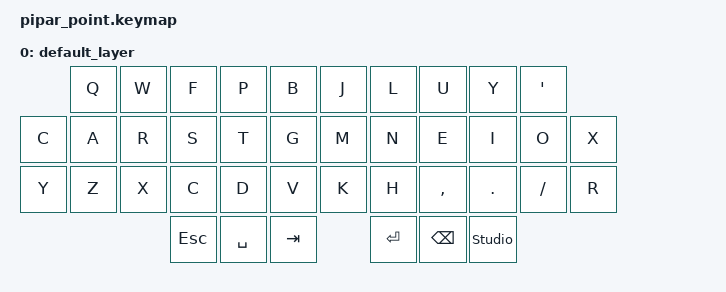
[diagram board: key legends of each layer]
#include <dt-bindings/zmk/keys.h>
#include <behaviors.dtsi>
/ {
    keymap {
        compatible = "zmk,keymap";
        default_layer {
            bindings = <
            &kp Q   &kp W   &kp F   &kp P   &kp B       &kp J   &kp L   &kp U       &kp Y       &kp SQT
    &kp C   &kp A   &kp R   &kp S   &kp T   &kp G       &kp M   &kp N   &kp E       &kp I       &kp O       &kp X
    &kp Y   &kp Z   &kp X   &kp C   &kp D   &kp V       &kp K   &kp H   &kp CMMA    &kp DOT     &kp SLASH   &kp R
                            &kp ESC &kp SPACE &kp TAB   &kp ENTER   &kp BSPC   &studio_unlock
            >;
        };
    };
};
